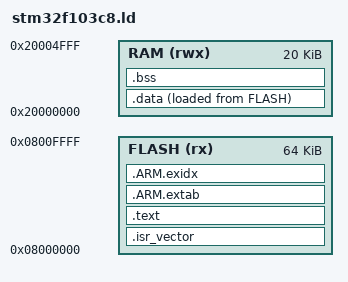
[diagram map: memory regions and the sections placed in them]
ENTRY(Reset_Handler)

MEMORY
{
    FLASH (rx)  : ORIGIN = 0x08000000, LENGTH = 64K
    RAM   (rwx) : ORIGIN = 0x20000000, LENGTH = 20K
}

_estack = ORIGIN(RAM) + LENGTH(RAM);
_stack_limit = _estack - 2048;

SECTIONS
{
    .isr_vector :
    {
        KEEP(*(.isr_vector))
    } > FLASH

    .text :
    {
        *(.text .text.*)
        *(.rodata .rodata.* .srodata .srodata.*)
        *(.glue_7 .glue_7t)
        . = ALIGN(4);
    } > FLASH

    .ARM.extab :
    {
        *(.ARM.extab* .gnu.linkonce.armextab.*)
    } > FLASH

    .ARM.exidx :
    {
        *(.ARM.exidx* .gnu.linkonce.armexidx.*)
        . = ALIGN(4);
    } > FLASH

    .data :
    {
        . = ALIGN(4);
        _sdata = .;
        *(.data .data.* .sdata .sdata.*)
        *(.ramfunc .ramfunc.*)
        *(.got .got.*)
        . = ALIGN(4);
        _edata = .;
    } > RAM AT > FLASH
    _sidata = LOADADDR(.data);
    /* Includes the initialized data's Flash load image, not just .text. */
    _flash_end = LOADADDR(.data) + SIZEOF(.data);

    .bss (NOLOAD) :
    {
        . = ALIGN(8);
        _sbss = .;
        *(.bss .bss.* .sbss .sbss.*)
        *(COMMON)
        . = ALIGN(8);
        _ebss = .;
        _end = .;
    } > RAM

    .ARM.attributes 0 : { *(.ARM.attributes) }
    /DISCARD/ : { *(.note.GNU-stack) *(.comment) }
}

ASSERT(_flash_end <= ORIGIN(FLASH) + LENGTH(FLASH), "Flash image exceeds 64 KiB")
ASSERT(_end <= _stack_limit, "Static SRAM leaves less than 2 KiB for the stack")
